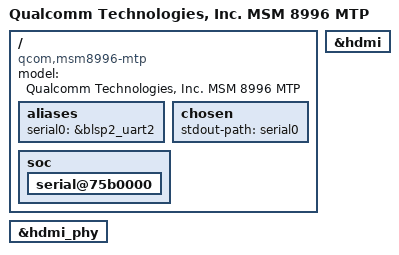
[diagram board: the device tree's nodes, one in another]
// SPDX-License-Identifier: GPL-2.0-only
/*
 * Copyright (c) 2014-2015, The Linux Foundation. All rights reserved.
 */

/dts-v1/;

#include "msm8996.dtsi"

/ {
	model = "Qualcomm Technologies, Inc. MSM 8996 MTP";
	compatible = "qcom,msm8996-mtp";

	aliases {
		serial0 = &blsp2_uart2;
	};

	chosen {
		stdout-path = "serial0";
	};

	soc {
		serial@75b0000 {
			status = "okay";
		};
	};
};

&hdmi {
	status = "okay";
};

&hdmi_phy {
	status = "okay";
};
